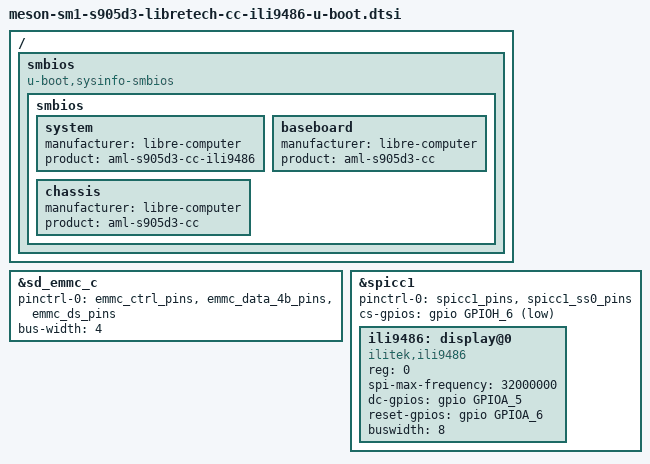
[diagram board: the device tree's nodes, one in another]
// SPDX-License-Identifier: (GPL-2.0+ OR MIT)
/*
 * Copyright (c) 2024 Da Xue <da@libre.computer>
 * ILI9486 SPI display support for AML-S905D3-CC
 */

#include <dt-bindings/gpio/gpio.h>
#include <dt-bindings/gpio/meson-g12a-gpio.h>
#include "meson-g12-common-u-boot.dtsi"

/ {
	smbios {
		compatible = "u-boot,sysinfo-smbios";

		smbios {
			system {
				manufacturer = "libre-computer";
				product = "aml-s905d3-cc-ili9486";
			};

			baseboard {
				manufacturer = "libre-computer";
				product = "aml-s905d3-cc";
			};

			chassis {
				manufacturer = "libre-computer";
				product = "aml-s905d3-cc";
			};
		};
	};
};

&sd_emmc_c {
	pinctrl-0 = <&emmc_ctrl_pins>, <&emmc_data_4b_pins>, <&emmc_ds_pins>;
	bus-width = <4>;
};

&spicc1 {
	status = "okay";
	pinctrl-0 = <&spicc1_pins>, <&spicc1_ss0_pins>;
	pinctrl-names = "default";
	cs-gpios = <&gpio GPIOH_6 GPIO_ACTIVE_LOW>;

	ili9486: display@0 {
		compatible = "ilitek,ili9486";
		reg = <0>;
		spi-max-frequency = <32000000>;
		dc-gpios = <&gpio GPIOA_5 GPIO_ACTIVE_HIGH>;
		reset-gpios = <&gpio GPIOA_6 GPIO_ACTIVE_HIGH>;
		buswidth = <8>;
	};
};
